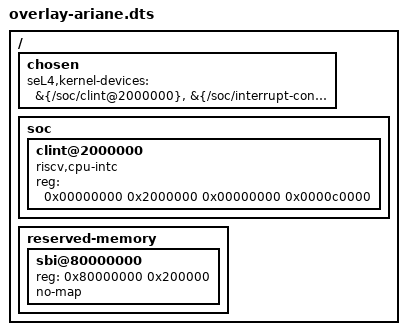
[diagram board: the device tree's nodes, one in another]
/*
 * Copyright 2020, Data61, CSIRO (ABN 41 687 119 230)
 * Copyright 2021, HENSOLDT Cyber
 *
 * SPDX-License-Identifier: GPL-2.0-only
 */

/ {
	chosen {
		seL4,kernel-devices =
            &{/soc/clint@2000000},
		    &{/soc/interrupt-controller@c000000};
	};

    /*
     * The size and address of the CLINT is from the memory map listed in the
     * CVA6 documentation. It can be found here:
     * https://docs.openhwgroup.org/projects/cva6-user-manual/05_cva6_apu/cva6_apu.html#memory-map
     */
    soc {
        clint@2000000 {
            compatible = "riscv,cpu-intc";
            reg = <0x00000000 0x2000000 0x00000000 0x0000c0000>;
        };
    };

    /* Reserve 2 MiB for SBI at the start of RAM (0x80000000 - 0x80200000). This
     * is exactly one "megapage" in the MMU table. It leaves plenty of space for
     * further SBI experimenting, given the known usage (as of June 2021) is:
     * - BBL: 76 KiB (= 0x13000)
     * - OpenSBI: 128 KiB (= 0x20000) with PMP protection
     */
    reserved-memory {
        #address-cells = <0x01>;
        #size-cells = <0x01>;
        ranges;
        sbi@80000000 {
            reg = <0x80000000 0x200000>;
            no-map;
        };
    };
};
